# DP32G030 register map
File version: 1.0
CPU: CM0 r0p0, little endian, no MPU, no FPU, 4 interrupt priority bits
Registers are 32-bit, read-write, reset 0x0 unless marked. A register's access mark holds for its fields unless they carry their own. Offsets are from the block's base; [hi:lo] are bit positions; {n}, {i} and the like mark numbered series.

## SARADC — SARADC unit
Base 0x400BA000
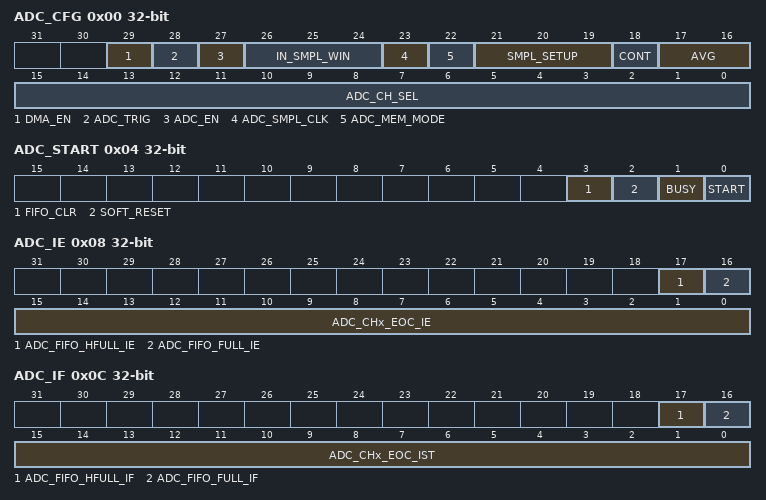
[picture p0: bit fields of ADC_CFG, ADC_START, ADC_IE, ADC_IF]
0x00 ADC_CFG — ADC configuration register
  [29] DMA_EN — DMA Read FIFO Enable 0: CPU reads FIFO 1: DMA Read FIFO
  [28] ADC_TRIG — ADC Trigger Source Selection 0: Select CPU to trigger ADC sampling 1: Select an external signal to trigger ADC sampling
  [27] ADC_EN — ADC enable bit 0: disable 1: Enable
  [26:24] IN_SMPL_WIN — ADC Internal Sample Clock Method Sample Window Selection 000: Sample setup time is held for 1 ADC clock cycle 001: Sample build time is held for 3 ADC clock cycles 010: Sample build time is held for 5 ADC clock cycles 011: Sample build time is held for 7 ADC clock cycles 100: Sample build time is held for 9 ADC clock cycles 101: Sample setup time is held for 11 ADC clock cycles 110: Sample build time is held for 13 ADC clock cycles 111: Sample build time is held for 15 ADC clock cycles
  [23] ADC_SMPL_CLK — ADC Sampling Mode Selection 1: Indicates that the ADC uses the internal sampling clock method. 0: Indicates that the ADC uses an external sampling clock.
  [22] ADC_MEM_MODE — ADC data storage method selection: 0: ADC data storage is in FIFO mode; 1: ADC data is stored in channel mode;
  [21:19] SMPL_SETUP — ADC External Sampling Clock Method Sampling Window Selection 000: Sample setup time is held for 1 ADC clock cycle 001: Sample setup time is held for 2 ADC clock cycles 010: Sample build time is held for 4 ADC clock cycles 011: Sample build time hold for 8 ADC clock cycles 100: Sample setup time is held for 16 ADC clock cycles 101: Sample build time is held for 32 ADC clock cycles 110: Sample build time is held for 64 ADC clock cycles 111: 128 ADC clock cycles of sample setup time retention
  [18] CONT — ADC Sampling Mode 0: single sample 1: Continuous sampling
  [17:16] AVG — One-start ADC Sample Averaging Configuration Register 00: 1 sample averaged 01: 2 samples averaged 10: 4 samples averaged 11: 8 samples averaged
  [15:0] ADC_CH_SEL — ADC Channel Select Register Bit15-bit0 corresponds to channel 15-channel 0. If the corresponding bit is configured as 1, it means the channel is valid.
0x04 ADC_START access per field — ADC boot register
  [3] FIFO_CLR rw write-1-clears — FIFO Clear Enable 0: disable 1: enable write 1 clear FIFO
  [2] SOFT_RESET rw — ADC Soft Reset 0: Reset active After the ADC is enabled, the ADC must be reset once before startup
  [1] BUSY ro — ADC Operating Status 1: Indicates busy
  [0] START rw — ADC start signal 0: disable 1: enable A write of 1 to this bit initiates a conversion. Can be used with ADC_CONT. If ADC_CONT is in one-shot sampling mode, after this position 1, the valid channels will be polled sequentially for sample conversion and the converted data will be saved in the FIFO or register of the corresponding channel. The hardware will automatically clear the data after the conversion is completed. If ADC_CONT is in continuous sampling mode, the position 1 means start ADC conversion, and clearing it means stop ADC conversion. After starting ADC conversion, the valid channels will be polled sequentially for sampling and conversion, and the converted data will be stored in the FIFO or register of the corresponding channel. After each conversion, it judges whether the bit is 1, if it is 1, the conversion will continue, if it is 0, the conversion will stop.
0x08 ADC_IE — ADC interrupt enable register
  [17] ADC_FIFO_HFULL_IE — ADC FIFO Half Full Interrupt Enable 0: disable 1: Enable
  [16] ADC_FIFO_FULL_IE — ADC FIFO full interrupt enable 0: disable 1: Enable
  [15:0] ADC_CHx_EOC_IE — ADC Channel x Data Conversion Complete Interrupt Enable
0x0C ADC_IF — ADC Interrupt status Register
  [17] ADC_FIFO_HFULL_IF write-1-clears — ADC FIFO half-full interrupt status write 1 clear
  [16] ADC_FIFO_FULL_IF — ADC FIFO Full Interrupt Status Write 1 Zero Clear
  [15:0] ADC_CHx_EOC_IST write-1-clears — ADC channel x data conversion complete interrupt status write 1 clear
{0x10+8i} ADC_CH{i}_STAT ro (i=0..14) — ADC{i} status register
  [0] ADC_CH_EOC — ADC Channel {i} Data Conversion Completion Flag 1: Indicates that the ADC has completed one sample conversion for channel {i}. The ADC can be cleared by writing 1 to the bit corresponding to ADC_IF.
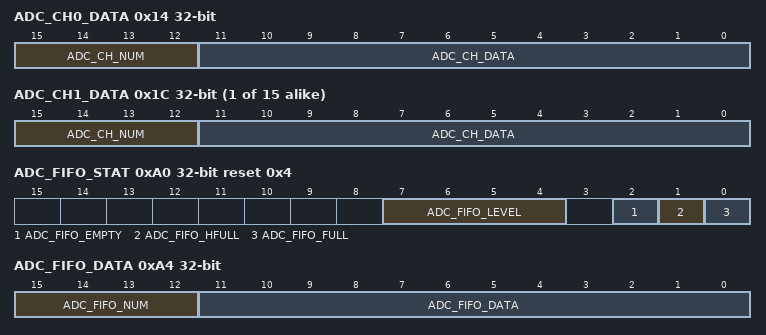
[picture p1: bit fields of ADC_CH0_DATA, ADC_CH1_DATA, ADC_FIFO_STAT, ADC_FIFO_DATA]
0x14 ADC_CH0_DATA ro — ADC0 data register
  [15:12] ADC_CH_NUM — Channel number corresponding to ADC data
  [11:0] ADC_CH_DATA — ADC Channel 0 Data Register Note: After the overflow, the data converted again will overwrite the old data
{0x14+8i} ADC_CH{i}_DATA ro (i=1..15) — ADC{i} data register
  [15:12] ADC_CH_NUM — Channel number corresponding to ADC data
  [11:0] ADC_CH_DATA — ADC Channel x Data Register Note: After the overflow, the data converted again will overwrite the old data
0x88 ADC_CH15_STAT ro — ADC15 status register
  [0] ADC_CH_EOC — ADC Channel 14 Data Conversion Completion Flag 1: Indicates that the ADC has completed one sample conversion for channel 14. The ADC can be cleared by writing 1 to the bit corresponding to ADC_IF.
0xA0 ADC_FIFO_STAT ro reset 0x4 — ADC FIFO status register
  [7:4] ADC_FIFO_LEVEL — ADC Data FIFO Water Level 0000: When it is not full, it means the FIFO has 0 data, when it is full, it means the FIFO has 16 data; 0001: Indicates that the FIFO has 1 data; 0010: Indicates that the FIFO has 2 data; 0011: Indicates that the FIFO has 3 data; 0100: Indicates that the FIFO has 4 data; 0101: Indicates that the FIFO has 5 data; 0110: Indicates that the FIFO has 6 data; 0111: Indicates that the FIFO has 7 data; 1000: Indicates that the FIFO has 8 data; 1001: Indicates that the FIFO has 9 data; 1010: Indicates that the FIFO has 10 data; 1011: Indicates that the FIFO has 11 data; 1100: Indicates that the FIFO has 12 data; 1101: Indicates that the FIFO has 13 data; 1110: Indicates that the FIFO has 14 data; 1111: Indicates that the FIFO has 15 data;
  [2] ADC_FIFO_EMPTY — ADC Data FIFO Empty Flag 1: Indicates that the FIFO is empty 0: Indicates that the FIFO is not empty
  [1] ADC_FIFO_HFULL — ADC Data FIFO Half Full Flag 1: Indicates that the FIFO is half full 0: Indicates that the FIFO is not half full
  [0] ADC_FIFO_FULL — ADC data FIFO full flag 1: Indicates that the FIFO is full 0: Indicates that the FIFO is not full
0xA4 ADC_FIFO_DATA ro
  [15:12] ADC_FIFO_NUM — Channel number corresponding to ADC data
  [11:0] ADC_FIFO_DATA — ADC Data FIFO Register Note: After an overflow, data that is converted again is discarded
0xB0 EXTTRIG_SEL — External signal trigger ADC
  [11:0] EXTTRIG_SEL — External Trigger ADC Sample Signal Selection Control Bit11-bit0: Indicates that they are used to control exttrig_in[11:0], respectively. Whether to trigger the control bit of ADC 0 means not valid; 1 means valid
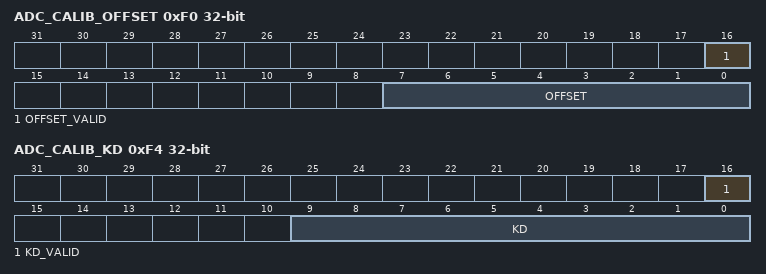
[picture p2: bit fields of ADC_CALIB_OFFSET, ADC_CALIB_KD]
0xF0 ADC_CALIB_OFFSET — ADC calibration OFFSET register
  [16] OFFSET_VALID — OFFSET Whether the data is valid or not
  [7:0] OFFSET — OFFSET value for ADC data calibration. The calculated OFFSET needs to be stored in this register. Used for calibration when using ADC.
0xF4 ADC_CALIB_KD — ADC calibration KD register
  [16] KD_VALID — Validity of KD data
  [9:0] KD — ADC data calibrates the fractional part of the K value. The fractional part of the calculated K value needs to be stored in this register. Used for calibration when using ADC. If K is greater than 1, the sign bit is 1. If K is less than 1, the sign bit is 0.
